AUTOSAR XML (schema 00046)
package /Composition_Lab
  sender receiver interface SRI_LightControl
    data LightControl: type=uint32
  sender receiver interface SRI_LightActuate
    data LightActuate: type=uint32
  sensor actuator sw component type LightStatus_SWC
    provide port Pp_SR_LightControl: provided-interface=SRI_LightControl
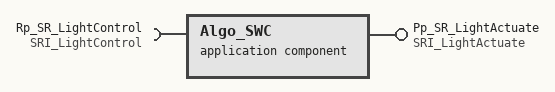
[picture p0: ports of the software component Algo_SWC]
  application sw component type Algo_SWC
    require port Rp_SR_LightControl: required-interface=SRI_LightControl
    provide port Pp_SR_LightActuate: provided-interface=SRI_LightActuate
  sensor actuator sw component type LightActuate_SWC
    require port Rp_SR_LightActuate: required-interface=SRI_LightActuate
  composition sw component type SW_Composite1
    provide port Pp_SR_LightActuate_Comp: provided-interface=SRI_LightActuate
    component LC_SA_SWC1: type=LightControlStatus_SWC
    component LA_SWC2: type=Algo_SWC
    connect LC_SA_SWC1.Pp_SR_LightControl -> LA_SWC2.Rp_SR_LightControl
    delegate LA_SWC2.Pp_SR_LightActuate <-> outer port Pp_SR_LightActuate_Comp
  composition sw component type TopLevel_CompositeSWC
    component SW_Composite_inst: type=SW_Composite1
    component LightActuate_SWC3: type=LightActuate_SWC
    connect SW_Composite1_inst.Pp_SR_LightActuate_Comp -> LightActuate_SWC3.Rp_SR_LightActuate
